# AT91SAM9G20 register map
Vendor: Atmel; File version: 20130207
Atmel AT91SAM9G20 device: ARM926EJ Embedded Microprocessor Unit, 400MHz, USB, Ethernet, 217 and 247 Pins (refer to http://www.atmel.com/devices/SAM9G20.aspx for more)
CPU: 
Registers are 32-bit, read-write, reset 0x0 unless marked. A register's access mark holds for its fields unless they carry their own. Offsets are from the block's base; lines under a group give offsets from that group; [hi:lo] are bit positions; {n}, {i} and the like mark numbered series; 'fields as' and 'values as' point back to an identical list; <NAME> marks a mode.

## Memory map
0x00500000 UHP size 0x100000 — USB Host Port
0xFFFA0000 TC0 size 0x4000 — Timer Counter 0
0xFFFA4000 UDP size 0x4000 — USB Device Port
0xFFFA8000 MCI size 0x4000 — MultiMedia Card Interface
0xFFFAC000 TWI size 0x4000 — Two-wire Interface
0xFFFB0000 USART0 size 0x4000 — Universal Synchronous Asynchronous Receiver Transmitter 0
0xFFFB4000 USART1 size 0x4000 — Universal Synchronous Asynchronous Receiver Transmitter 1
0xFFFB8000 USART2 size 0x4000 — Universal Synchronous Asynchronous Receiver Transmitter 2
0xFFFBC000 SSC0 size 0x4000 — Synchronous Serial Controller 0
0xFFFC0000 ISI size 0x4000 — Image Sensor Interface
0xFFFC4000 EMAC size 0x4000 — Ethernet MAC 10/100
0xFFFC8000 SPI0 size 0x4000 — Serial Peripheral Interface 0
0xFFFCC000 SPI1 size 0x4000 — Serial Peripheral Interface 1
0xFFFD0000 USART3 size 0x4000 — Universal Synchronous Asynchronous Receiver Transmitter 3
0xFFFD4000 USART4 size 0x4000 — Universal Synchronous Asynchronous Receiver Transmitter 4
0xFFFD8000 USART5 size 0x4000 — Universal Synchronous Asynchronous Receiver Transmitter 5
0xFFFDC000 TC1 size 0x4000 — Timer Counter 1
0xFFFE0000 ADC size 0x4000 — Analog-to-Digital Converter
0xFFFFEA00 SDRAMC size 0x200 — SDRAM Controller
0xFFFFEC00 SMC size 0x200 — Static Memory Controller
0xFFFFEE00 MATRIX size 0x200 — AHB Bus Matrix
0xFFFFF000 AIC size 0x200 — Advanced Interrupt Controller
0xFFFFF200 DBGU size 0x200 — Debug Unit
0xFFFFF400 PIOA size 0x200 — Parallel Input/Output Controller A
0xFFFFF600 PIOB size 0x200 — Parallel Input/Output Controller B
0xFFFFF800 PIOC size 0x200 — Parallel Input/Output Controller C
0xFFFFFC00 PMC size 0x200 — Power Management Controller
0xFFFFFD00 RSTC size 0x200 — Reset Controller
0xFFFFFD10 SHDWC size 0x200 — Shutdown Controller
0xFFFFFD20 RTT size 0x200 — Real-time Timer
0xFFFFFD30 PIT size 0x200 — Periodic Interval Timer
0xFFFFFD40 WDT size 0x200 — Watchdog Timer
0xFFFFFD50 GPBR size 0x200 — General Purpose Backup Register

## Interrupts
0 FIQ (AIC)
1 DBGU
2 PIOA
3 PIOB
4 PIOC
5 ADC
6 USART0
7 USART1
8 USART2
9 MCI
10 UDP
11 TWI
12 SPI0
13 SPI1
14 SSC0
17 TC0
18 TC1 (TC0)
19 TC2 (TC0)
20 UHP
21 EMAC
22 ISI
23 USART3
24 USART4
25 USART5
26 TC3 (TC1)
27 TC4 (TC1)
28 TC5 (TC1)
29 IRQ0 (AIC)
30 IRQ1 (AIC)
31 IRQ2 (AIC)

## SMC — Static Memory Controller
Base 0xFFFFEC00; register names take the prefix SMC_
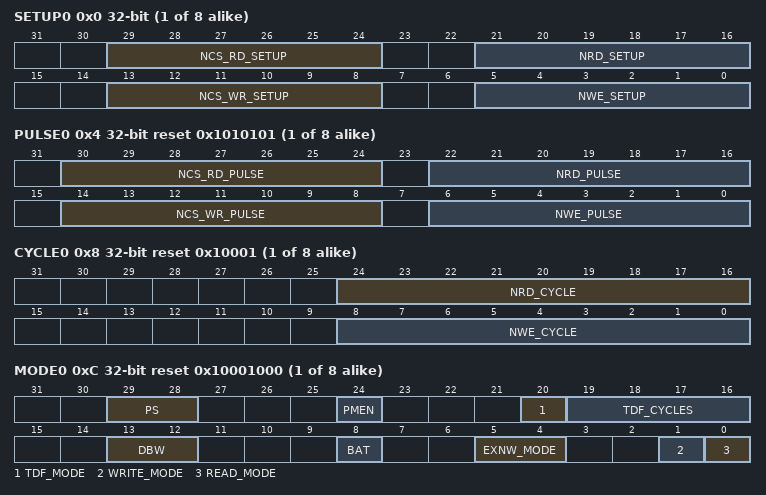
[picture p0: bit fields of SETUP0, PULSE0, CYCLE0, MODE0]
{0x0+0x10*i} SETUP{i} reset not defined (i=0..7) — SMC Setup Register (CS_number = {i})
  [29:24] NCS_RD_SETUP — NCS Setup Length in READ Access
  [21:16] NRD_SETUP — NRD Setup Length
  [13:8] NCS_WR_SETUP — NCS Setup Length in WRITE Access
  [5:0] NWE_SETUP — NWE Setup Length
{0x4+0x10*i} PULSE{i} reset 0x1010101 (i=0..7) — SMC Pulse Register (CS_number = {i})
  [30:24] NCS_RD_PULSE — NCS Pulse Length in READ Access
  [22:16] NRD_PULSE — NRD Pulse Length
  [14:8] NCS_WR_PULSE — NCS Pulse Length in WRITE Access
  [6:0] NWE_PULSE — NWE Pulse Length
{0x8+0x10*i} CYCLE{i} reset 0x10001 (i=0..7) — SMC Cycle Register (CS_number = {i})
  [24:16] NRD_CYCLE — Total Read Cycle Length
  [8:0] NWE_CYCLE — Total Write Cycle Length
{0xC+0x10*i} MODE{i} reset 0x10001000 (i=0..7) — SMC Mode Register (CS_number = {i})
  [29:28] PS — Page Size
  [24] PMEN — Page Mode Enabled
  [20] TDF_MODE — TDF Optimization
  [19:16] TDF_CYCLES — Data Float Time
  [13:12] DBW — Data Bus Width
  [8] BAT — Byte Access Type
  [5:4] EXNW_MODE — NWAIT Mode
  [1] WRITE_MODE
  [0] READ_MODE
